# EFM32GG11B820F2048GL152 register map
File version: 4.0.0
CPU: CM4 r0p1, little endian, MPU, FPU, 3 interrupt priority bits
Registers are 32-bit, read-write, reset 0x0 unless marked. A register's access mark holds for its fields unless they carry their own. Offsets are from the block's base; [hi:lo] are bit positions; {n}, {i} and the like mark numbered series.

## SMU
Base 0x40020000
0x0C IF ro — Interrupt Flag Register
  [0] PPUPRIV — PPU Privilege Interrupt Flag
0x10 IFS wo — Interrupt Flag Set Register
  [0] PPUPRIV — Set PPUPRIV Interrupt Flag
0x14 IFC wo — Interrupt Flag Clear Register
  [0] PPUPRIV — Clear PPUPRIV Interrupt Flag
0x18 IEN — Interrupt Enable Register
  [0] PPUPRIV — PPUPRIV Interrupt Enable
0x40 PPUCTRL — PPU Control Register
  [0] ENABLE
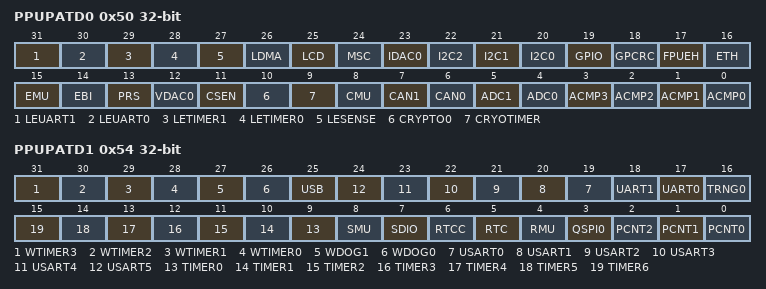
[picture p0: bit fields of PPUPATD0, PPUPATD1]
0x50 PPUPATD0 — PPU Privilege Access Type Descriptor 0
  [31] LEUART1 — Low Energy UART 1 access control bit
  [30] LEUART0 — Low Energy UART 0 access control bit
  [29] LETIMER1 — Low Energy Timer 1 access control bit
  [28] LETIMER0 — Low Energy Timer 0 access control bit
  [27] LESENSE — Low Energy Sensor Interface access control bit
  [26] LDMA — Linked Direct Memory Access Controller access control bit
  [25] LCD — Liquid Crystal Display Controller access control bit
  [24] MSC — Memory System Controller access control bit
  [23] IDAC0 — Current Digital to Analog Converter 0 access control bit
  [22] I2C2 — I2C 2 access control bit
  [21] I2C1 — I2C 1 access control bit
  [20] I2C0 — I2C 0 access control bit
  [19] GPIO — General purpose Input/Output access control bit
  [18] GPCRC — General Purpose CRC access control bit
  [17] FPUEH — FPU Exception Handler access control bit
  [16] ETH — Ethernet Controller access control bit
  [15] EMU — Energy Management Unit access control bit
  [14] EBI — External Bus Interface access control bit
  [13] PRS — Peripheral Reflex System access control bit
  [12] VDAC0 — Digital to Analog Converter 0 access control bit
  [11] CSEN — Capacitive touch sense module access control bit
  [10] CRYPTO0 — Advanced Encryption Standard Accelerator access control bit
  [9] CRYOTIMER — CRYOTIMER access control bit
  [8] CMU — Clock Management Unit access control bit
  [7] CAN1 — CAN 1 access control bit
  [6] CAN0 — CAN 0 access control bit
  [5] ADC1 — Analog to Digital Converter 0 access control bit
  [4] ADC0 — Analog to Digital Converter 0 access control bit
  [3] ACMP3 — Analog Comparator 3 access control bit
  [2] ACMP2 — Analog Comparator 1 access control bit
  [1] ACMP1 — Analog Comparator 1 access control bit
  [0] ACMP0 — Analog Comparator 0 access control bit
0x54 PPUPATD1 — PPU Privilege Access Type Descriptor 1
  [31] WTIMER3 — Wide Timer 3 access control bit
  [30] WTIMER2 — Wide Timer 2 access control bit
  [29] WTIMER1 — Wide Timer 0 access control bit
  [28] WTIMER0 — Wide Timer 0 access control bit
  [27] WDOG1 — Watchdog access control bit
  [26] WDOG0 — Watchdog access control bit
  [25] USB — Universal Serial Bus Interface access control bit
  [n+19] USART{n} (n=0..5) — Universal Synchronous/Asynchronous Receiver/Transmitter {n} access control bit
  [18] UART1 — Universal Asynchronous Receiver/Transmitter 1 access control bit
  [17] UART0 — Universal Asynchronous Receiver/Transmitter 0 access control bit
  [16] TRNG0 — True Random Number Generator 0 access control bit
  [n+9] TIMER{n} (n=0..6) — Timer {n} access control bit
  [8] SMU — Security Management Unit access control bit
  [7] SDIO — SDIO Controller access control bit
  [6] RTCC — Real-Time Counter and Calendar access control bit
  [5] RTC — Real-Time Counter access control bit
  [4] RMU — Reset Management Unit access control bit
  [3] QSPI0 — Quad-SPI access control bit
  [2] PCNT2 — Pulse Counter 2 access control bit
  [1] PCNT1 — Pulse Counter 1 access control bit
  [0] PCNT0 — Pulse Counter 0 access control bit
0x58 PPUPATD2 reset not defined — PPU Privilege Access Type Descriptor 2
0x90 PPUFS ro — PPU Fault Status
  [6:0] PERIPHID
    0=ACMP0 (Analog Comparator 0); 1=ACMP1 (Analog Comparator 1); 2=ACMP2 (Analog Comparator 1); 3=ACMP3 (Analog Comparator 3); 4=ADC0 (Analog to Digital Converter 0); 5=ADC1 (Analog to Digital Converter 0); 6=CAN0; 7=CAN1; 8=CMU (Clock Management Unit); 9=CRYOTIMER; 10=CRYPTO0 (Advanced Encryption Standard Accelerator); 11=CSEN (Capacitive touch sense module); 12=VDAC0 (Digital to Analog Converter 0); 13=PRS (Peripheral Reflex System); 14=EBI (External Bus Interface); 15=EMU (Energy Management Unit); 16=ETH (Ethernet Controller); 17=FPUEH (FPU Exception Handler); 18=GPCRC (General Purpose CRC); 19=GPIO (General purpose Input/Output); 20=I2C0; 21=I2C1; 22=I2C2; 23=IDAC0 (Current Digital to Analog Converter 0); 24=MSC (Memory System Controller); 25=LCD (Liquid Crystal Display Controller); 26=LDMA (Linked Direct Memory Access Controller); 27=LESENSE (Low Energy Sensor Interface); 28=LETIMER0 (Low Energy Timer 0); 29=LETIMER1 (Low Energy Timer 1); 30=LEUART0 (Low Energy UART 0); 31=LEUART1 (Low Energy UART 1); 32=PCNT0 (Pulse Counter 0); 33=PCNT1 (Pulse Counter 1); 34=PCNT2 (Pulse Counter 2); 35=QSPI0 (Quad-SPI); 36=RMU (Reset Management Unit); 37=RTC (Real-Time Counter); 38=RTCC (Real-Time Counter and Calendar); 39=SDIO (SDIO Controller); 40=SMU (Security Management Unit); {v}=TIMER{v-41} (v=41..47); 48=TRNG0 (True Random Number Generator 0); 49=UART0 (Universal Asynchronous Receiver/Transmitter 0); 50=UART1 (Universal Asynchronous Receiver/Transmitter 1); {v}=USART{v-51} (Universal Synchronous/Asynchronous Receiver/Transmitter {v-51}) (v=51..56); 57=USB (Universal Serial Bus Interface); 58=WDOG0 (Watchdog); 59=WDOG1 (Watchdog); 60=WTIMER0 (Wide Timer 0); 61=WTIMER1 (Wide Timer 0); 62=WTIMER2 (Wide Timer 2); 63=WTIMER3 (Wide Timer 3)
